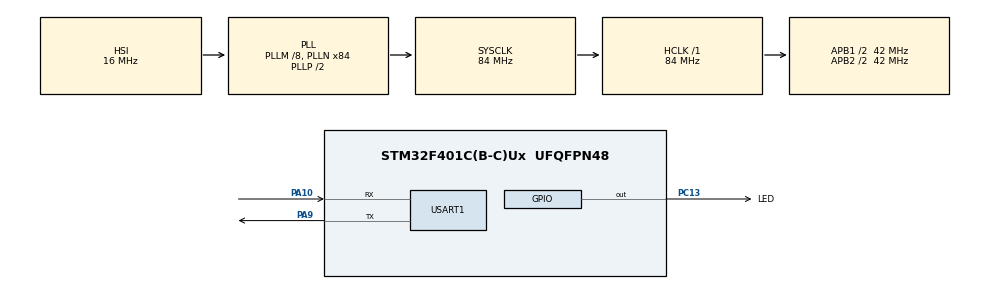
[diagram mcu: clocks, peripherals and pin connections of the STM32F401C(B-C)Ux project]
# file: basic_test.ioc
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Mcu.Family=STM32F4
Mcu.Name=STM32F401C(B-C)Ux
Mcu.Package=UFQFPN48
NVIC.PriorityGroup=NVIC_PRIORITYGROUP_4
PA10.Mode=Asynchronous
PA10.Signal=USART1_RX
PA13.Mode=Serial_Wire
PA13.Signal=SYS_JTMS-SWDIO
PA14.Mode=Serial_Wire
PA14.Signal=SYS_JTCK-SWCLK
PA9.Mode=Asynchronous
PA9.Signal=USART1_TX
PC13-ANTI_TAMP.GPIO_Label=LED
PC13-ANTI_TAMP.PinState=GPIO_PIN_RESET
PC13-ANTI_TAMP.Signal=GPIO_Output
PH0\ -\ OSC_IN.Mode=HSE-External-Oscillator
PH0\ -\ OSC_IN.Signal=RCC_OSC_IN
PH1\ -\ OSC_OUT.Mode=HSE-External-Oscillator
PH1\ -\ OSC_OUT.Signal=RCC_OSC_OUT
ProjectManager.HeapSize=0x200
ProjectManager.StackSize=0x400
ProjectManager.TargetToolchain=Makefile
RCC.48MHZClocksFreq_Value=42000000
RCC.AHBFreq_Value=84000000
RCC.APB1CLKDivider=RCC_HCLK_DIV2
RCC.APB1Freq_Value=42000000
RCC.APB1TimFreq_Value=84000000
RCC.APB2CLKDivider=RCC_HCLK_DIV2
RCC.APB2Freq_Value=42000000
RCC.APB2TimFreq_Value=84000000
RCC.CortexFreq_Value=84000000
RCC.HCLKFreq_Value=84000000
RCC.HSE_VALUE=25000000
RCC.HSI_VALUE=16000000
RCC.LSE_VALUE=32768
RCC.PLLM=8
RCC.PLLN=84
RCC.RCC_RTC_Clock_Source=RCC_RTCCLKSOURCE_LSI
RCC.RCC_RTC_Clock_SourceVirtual=RCC_RTCCLKSOURCE_LSE
RCC.SYSCLKFreq_VALUE=84000000
RCC.SYSCLKSource=RCC_SYSCLKSOURCE_PLLCLK
RCC.VCOOutputFreq_Value=168000000
USART1.VirtualMode=VM_ASYNC
board=custom

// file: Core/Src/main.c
/* USER CODE BEGIN Header */
/**
  ******************************************************************************
  * @file           : main.c
  * @brief          : Main program body
  ******************************************************************************
  * @attention
  *
  * <h2><center>&copy; Copyright (c) 2021 STMicroelectronics.
  * All rights reserved.</center></h2>
  *
  * This software component is licensed by ST under BSD 3-Clause license,
  * the "License"; You may not use this file except in compliance with the
  * License. You may obtain a copy of the License at:
  *                        opensource.org/licenses/BSD-3-Clause
  *
  ******************************************************************************
  */
/* USER CODE END Header */
#include "main.h"

/* USER CODE BEGIN Includes */
#include <stdio.h>
/* USER CODE END Includes */

UART_HandleTypeDef huart1;

/* USER CODE BEGIN PV */

#ifdef __GNUC__
int _write(int fd, char *ptr, int len)
{
  HAL_UART_Transmit(&huart1, (uint8_t*)ptr, len, 0xFFFF);
  return len;
}
#endif

char a='a';

/* USER CODE END PV */

void SystemClock_Config(void);
static void MX_GPIO_Init(void);
static void MX_USART1_UART_Init(void);

int main(void)
{

  /* MCU Configuration--------------------------------------------------------*/

  /* Reset of all peripherals, Initializes the Flash interface and the Systick. */
  HAL_Init();

  /* Configure the system clock */
  SystemClock_Config();

  /* Initialize all configured peripherals */
  MX_GPIO_Init();
  MX_USART1_UART_Init();
  /* USER CODE BEGIN 2 */
  printf("welcome to a new world! \r\n");
  /* USER CODE END 2 */

  /* Infinite loop */
  /* USER CODE BEGIN WHILE */
  while (1)
  {
    //HAL_UART_Transmit(&huart1,(uint8_t *)&a,1,0xFFFF);
    printf("welcome to a new world! \r\n");
    HAL_Delay(1000);
    HAL_GPIO_WritePin(LED_GPIO_Port, LED_Pin, GPIO_PIN_RESET);
    HAL_Delay(1000);
    HAL_GPIO_WritePin(LED_GPIO_Port, LED_Pin, GPIO_PIN_SET);
    /* USER CODE END WHILE */

  }
}

void SystemClock_Config(void)
{
  RCC_OscInitTypeDef RCC_OscInitStruct = {0};
  RCC_ClkInitTypeDef RCC_ClkInitStruct = {0};

  /** Configure the main internal regulator output voltage
  */
  __HAL_RCC_PWR_CLK_ENABLE();
  __HAL_PWR_VOLTAGESCALING_CONFIG(PWR_REGULATOR_VOLTAGE_SCALE2);

  /** Initializes the RCC Oscillators according to the specified parameters
  * in the RCC_OscInitTypeDef structure.
  */
  RCC_OscInitStruct.OscillatorType = RCC_OSCILLATORTYPE_HSI;
  RCC_OscInitStruct.HSIState = RCC_HSI_ON;
  RCC_OscInitStruct.HSICalibrationValue = RCC_HSICALIBRATION_DEFAULT;
  RCC_OscInitStruct.PLL.PLLState = RCC_PLL_ON;
  RCC_OscInitStruct.PLL.PLLSource = RCC_PLLSOURCE_HSI;
  RCC_OscInitStruct.PLL.PLLM = 8;
  RCC_OscInitStruct.PLL.PLLN = 84;
  RCC_OscInitStruct.PLL.PLLP = RCC_PLLP_DIV2;
  RCC_OscInitStruct.PLL.PLLQ = 4;
  if (HAL_RCC_OscConfig(&RCC_OscInitStruct) != HAL_OK)
  {
    Error_Handler();
  }

  /** Initializes the CPU, AHB and APB buses clocks
  */
  RCC_ClkInitStruct.ClockType = RCC_CLOCKTYPE_HCLK|RCC_CLOCKTYPE_SYSCLK
                              |RCC_CLOCKTYPE_PCLK1|RCC_CLOCKTYPE_PCLK2;
  RCC_ClkInitStruct.SYSCLKSource = RCC_SYSCLKSOURCE_PLLCLK;
  RCC_ClkInitStruct.AHBCLKDivider = RCC_SYSCLK_DIV1;
  RCC_ClkInitStruct.APB1CLKDivider = RCC_HCLK_DIV2;
  RCC_ClkInitStruct.APB2CLKDivider = RCC_HCLK_DIV2;

  if (HAL_RCC_ClockConfig(&RCC_ClkInitStruct, FLASH_LATENCY_2) != HAL_OK)
  {
    Error_Handler();
  }
}

static void MX_USART1_UART_Init(void)
{

  huart1.Instance = USART1;
  huart1.Init.BaudRate = 115200;
  huart1.Init.WordLength = UART_WORDLENGTH_8B;
  huart1.Init.StopBits = UART_STOPBITS_1;
  huart1.Init.Parity = UART_PARITY_NONE;
  huart1.Init.Mode = UART_MODE_TX_RX;
  huart1.Init.HwFlowCtl = UART_HWCONTROL_NONE;
  huart1.Init.OverSampling = UART_OVERSAMPLING_16;
  if (HAL_UART_Init(&huart1) != HAL_OK)
  {
    Error_Handler();
  }

}

static void MX_GPIO_Init(void)
{
  GPIO_InitTypeDef GPIO_InitStruct = {0};

  /* GPIO Ports Clock Enable */
  __HAL_RCC_GPIOC_CLK_ENABLE();
  __HAL_RCC_GPIOH_CLK_ENABLE();
  __HAL_RCC_GPIOA_CLK_ENABLE();

  /*Configure GPIO pin Output Level */
  HAL_GPIO_WritePin(LED_GPIO_Port, LED_Pin, GPIO_PIN_RESET);

  /*Configure GPIO pin : LED_Pin */
  GPIO_InitStruct.Pin = LED_Pin;
  GPIO_InitStruct.Mode = GPIO_MODE_OUTPUT_PP;
  GPIO_InitStruct.Pull = GPIO_NOPULL;
  GPIO_InitStruct.Speed = GPIO_SPEED_FREQ_LOW;
  HAL_GPIO_Init(LED_GPIO_Port, &GPIO_InitStruct);

}

void Error_Handler(void)
{
  __disable_irq();
  while (1)
  {
  }
}
